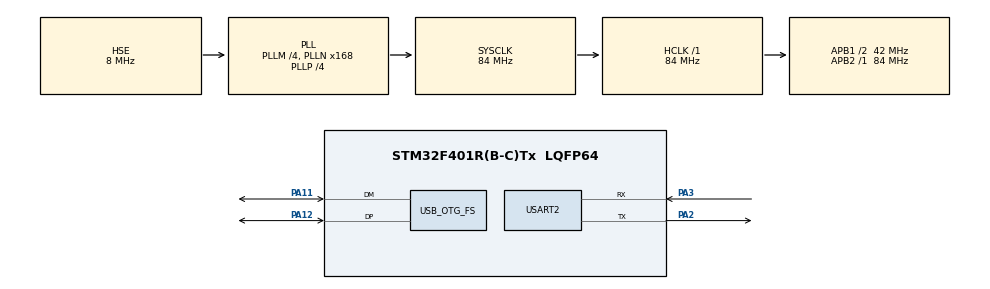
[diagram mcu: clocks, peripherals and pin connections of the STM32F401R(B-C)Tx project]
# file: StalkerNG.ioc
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Mcu.Family=STM32F4
Mcu.Name=STM32F401R(B-C)Tx
Mcu.Package=LQFP64
NVIC.OTG_FS_IRQn=true\:0\:0\:false\:false\:true\:false\:true\:true
NVIC.PriorityGroup=NVIC_PRIORITYGROUP_4
NVIC.TIM1_UP_TIM10_IRQn=true\:15\:0\:false\:false\:true\:false\:true\:true
NVIC.TimeBase=TIM1_UP_TIM10_IRQn
NVIC.TimeBaseIP=TIM1
PA11.Mode=Host_Only
PA11.Signal=USB_OTG_FS_DM
PA12.Mode=Host_Only
PA12.Signal=USB_OTG_FS_DP
PA2.Mode=Asynchronous
PA2.Signal=USART2_TX
PA3.Mode=Asynchronous
PA3.Signal=USART2_RX
PH0\ -\ OSC_IN.Mode=HSE-External-Oscillator
PH0\ -\ OSC_IN.Signal=RCC_OSC_IN
PH1\ -\ OSC_OUT.Mode=HSE-External-Oscillator
PH1\ -\ OSC_OUT.Signal=RCC_OSC_OUT
ProjectManager.HeapSize=0x200
ProjectManager.StackSize=0x400
ProjectManager.TargetToolchain=Makefile
RCC.48MHZClocksFreq_Value=48000000
RCC.AHBFreq_Value=84000000
RCC.APB1CLKDivider=RCC_HCLK_DIV2
RCC.APB1Freq_Value=42000000
RCC.APB1TimFreq_Value=84000000
RCC.APB2Freq_Value=84000000
RCC.APB2TimFreq_Value=84000000
RCC.CortexFreq_Value=84000000
RCC.HCLKFreq_Value=84000000
RCC.HSE_VALUE=8000000
RCC.HSI_VALUE=16000000
RCC.LSE_VALUE=32768
RCC.PLLM=4
RCC.PLLN=168
RCC.PLLP=RCC_PLLP_DIV4
RCC.PLLQ=7
RCC.SYSCLKFreq_VALUE=84000000
RCC.SYSCLKSource=RCC_SYSCLKSOURCE_PLLCLK
RCC.VCOOutputFreq_Value=336000000
USART2.VirtualMode=VM_ASYNC
USB_HOST.USBH_DEBUG_LEVEL=3
USB_HOST.USBH_HandleTypeDef=hUsbHostFS
USB_HOST.USBH_MAX_DATA_BUFFER=1024
USB_HOST.USBH_MAX_NUM_CONFIGURATION=2
USB_HOST.USBH_MAX_NUM_ENDPOINTS=4
USB_HOST.USBH_MAX_NUM_SUPPORTED_CLASS=4
USB_HOST.USBH_MAX_SIZE_CONFIGURATION=512
USB_HOST.VirtualModeFS=Hid
USB_OTG_FS.VirtualMode=Host_Only
USB_OTG_FS.phy_itface=HCD_PHY_EMBEDDED
VP_SYS_VS_tim1.Mode=TIM1
VP_USB_HOST_VS_USB_HOST_HID_FS.Mode=HID_FS
board=custom

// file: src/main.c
/* USER CODE BEGIN Header */
/**
  ******************************************************************************
  * @file           : main.c
  * @brief          : Main program body
  ******************************************************************************
  * @attention
  *
  * Copyright (c) 2025 STMicroelectronics.
  * All rights reserved.
  *
  * This software is licensed under terms that can be found in the LICENSE file
  * in the root directory of this software component.
  * If no LICENSE file comes with this software, it is provided AS-IS.
  *
  ******************************************************************************
  */
/* USER CODE END Header */
#include <stdio.h>
#include "main.h"
#include "usb_host.h"

/* USER CODE BEGIN Includes */
#include "usbh_hid.h"
#include "usbh_hid_keybd.h"
/* USER CODE END Includes */

UART_HandleTypeDef huart2;

/* USER CODE BEGIN PV */
extern ApplicationTypeDef Appli_state;
extern USBH_HandleTypeDef hUsbHostFS;
/* USER CODE END PV */

void SystemClock_Config(void);
static void MX_GPIO_Init(void);
static void MX_USART2_UART_Init(void);
void MX_USB_HOST_Process(void);

/* USER CODE BEGIN 0 */
#ifdef __GNUC__
  /* With GCC, small printf (option LD Linker->Libraries->Small printf
     set to 'Yes') calls __io_putchar() */
  #define PUTCHAR_PROTOTYPE int __io_putchar(int ch)
#else
  #define PUTCHAR_PROTOTYPE int fputc(int ch, FILE *f)
#endif /* __GNUC__ */

/**
  * @brief  Retargets the C library printf function to the USART.
  * @param  None
  * @retval None
  */
PUTCHAR_PROTOTYPE
{
  /* Place your implementation of fputc here */
  /* e.g. write a character to the USART2 and Loop until the end of transmission */
  HAL_UART_Transmit(&huart2, (uint8_t *)&ch, 1, 0xFFFF);

  return ch;
}
/* USER CODE END 0 */
#include "FreeRTOS.h"
#include "task.h"
void vApplicationStackOverflowHook( TaskHandle_t xTask, char *pcTaskName )
{
	( void ) pcTaskName;
	( void ) xTask;
	printf("%s\r\n", __PRETTY_FUNCTION__);
	for (;;);
}

void vApplicationMallocFailedHook( void )
{
	/* The malloc failed hook is enabled by setting
	configUSE_MALLOC_FAILED_HOOK to 1 in FreeRTOSConfig.h.
	Called if a call to pvPortMalloc() fails because there is insufficient
	free memory available in the FreeRTOS heap. pvPortMalloc() is called
	internally by FreeRTOS API functions that create tasks, queues, software
	timers, and semaphores. The size of the FreeRTOS heap is set by the
	configTOTAL_HEAP_SIZE configuration constant in FreeRTOSConfig.h. */
	printf("%s\r\n", __PRETTY_FUNCTION__);
	for( ;; );
}
extern void vApplicationMallocFailedHook( void );

void vApplicationTickHook( void )
{
    /* This function will be called by each tick interrupt if
    configUSE_TICK_HOOK is set to 1 in FreeRTOSConfig.h.
    User code can be added here, but the tick hook is normally
    just used to increment a counter to simulate a software clock. */
}

void LedTask(void *argument)
{
	printf("LedTask Running...\n\r");
	while (1)
	{
		led_on();
		vTaskDelay(pdMS_TO_TICKS(200));
		led_off();
		vTaskDelay(pdMS_TO_TICKS(200));
	}
}

void USBTask(void *argument)
{
	HID_KEYBD_Info_TypeDef *keybd_info;
	static char last_char = 0;
	char c;
	ApplicationTypeDef last_state = APPLICATION_DISCONNECT;

	printf("USBTask Running...\r\n");

	while (1)
	{
		/* USER CODE END WHILE */
		MX_USB_HOST_Process();

		/* USER CODE BEGIN 3 */

		switch (Appli_state)
		{
			case APPLICATION_READY:
			  if (last_state != Appli_state)
				  printf("APPLICATION_READY\r\n");

			  keybd_info = USBH_HID_GetKeybdInfo(&hUsbHostFS);

			  if(keybd_info != NULL)
			  {
				c = USBH_HID_GetASCIICode(keybd_info);
				if (c != 0 && c != last_char)
				{
				  printf("--> KeyCode: %c\n\r", c);
				  fflush(stdout);
				  last_char = c;
				}
				else if (c == 0)
				{
				  last_char = 0; // Reset on key release
				}
			  }
		  break;

		 case APPLICATION_IDLE:
			if (last_state != Appli_state)
				printf("APPLICATION IDLE\r\n");
			break;

		case APPLICATION_START:
			if (last_state != Appli_state)
				printf("APPLICATION START\r\n");
			break;

		case APPLICATION_DISCONNECT:
			if (last_state != Appli_state)
				printf("APPLICATION DISCONNECT\r\n");
		default:
			break;
		}
		last_state = Appli_state;
		/* USER CODE END 3 */
	}

}

int main(void)
{

  /* MCU Configuration--------------------------------------------------------*/

  /* Reset of all peripherals, Initializes the Flash interface and the Systick. */
  HAL_Init();

  /* Configure the system clock */
  SystemClock_Config();

  /* Initialize all configured peripherals */
  MX_GPIO_Init();
  MX_USART2_UART_Init();
  /* Da questo momento la printf e' su debug */
  printf("MAIN CALLED\r\n");
  MX_USB_HOST_Init();
  /* USER CODE BEGIN 2 */
  if ( xTaskCreate( USBTask, "USB Task", configMINIMAL_STACK_SIZE * 4, NULL, tskIDLE_PRIORITY + 2, NULL) != pdPASS )
  {
	printf("Error on creating USB task\n\r");
	while (1) ;;
  }

  if ( xTaskCreate( LedTask, "Led Task", configMINIMAL_STACK_SIZE * 4, NULL, tskIDLE_PRIORITY + 2, NULL) != pdPASS )
  {
	printf("Error on creating LED task\n\r");
	while (1) ;;
  }

  vTaskStartScheduler();

  /* USER CODE END 2 */

  /* Infinite loop */
  /* USER CODE BEGIN WHILE */
  while (1)
  {
  }
}

void SystemClock_Config(void)
{
  RCC_OscInitTypeDef RCC_OscInitStruct = {0};
  RCC_ClkInitTypeDef RCC_ClkInitStruct = {0};

  /** Configure the main internal regulator output voltage
  */
  __HAL_RCC_PWR_CLK_ENABLE();
  __HAL_PWR_VOLTAGESCALING_CONFIG(PWR_REGULATOR_VOLTAGE_SCALE2);

  /** Initializes the RCC Oscillators according to the specified parameters
  * in the RCC_OscInitTypeDef structure.
  */
  RCC_OscInitStruct.OscillatorType = RCC_OSCILLATORTYPE_HSE;
  RCC_OscInitStruct.HSEState = RCC_HSE_ON;
  RCC_OscInitStruct.PLL.PLLState = RCC_PLL_ON;
  RCC_OscInitStruct.PLL.PLLSource = RCC_PLLSOURCE_HSE;
  RCC_OscInitStruct.PLL.PLLM = 4;
  RCC_OscInitStruct.PLL.PLLN = 168;
  RCC_OscInitStruct.PLL.PLLP = RCC_PLLP_DIV4;
  RCC_OscInitStruct.PLL.PLLQ = 7;
  if (HAL_RCC_OscConfig(&RCC_OscInitStruct) != HAL_OK)
  {
    Error_Handler();
  }

  /** Initializes the CPU, AHB and APB buses clocks
  */
  RCC_ClkInitStruct.ClockType = RCC_CLOCKTYPE_HCLK|RCC_CLOCKTYPE_SYSCLK
                              |RCC_CLOCKTYPE_PCLK1|RCC_CLOCKTYPE_PCLK2;
  RCC_ClkInitStruct.SYSCLKSource = RCC_SYSCLKSOURCE_PLLCLK;
  RCC_ClkInitStruct.AHBCLKDivider = RCC_SYSCLK_DIV1;
  RCC_ClkInitStruct.APB1CLKDivider = RCC_HCLK_DIV2;
  RCC_ClkInitStruct.APB2CLKDivider = RCC_HCLK_DIV1;

  if (HAL_RCC_ClockConfig(&RCC_ClkInitStruct, FLASH_LATENCY_2) != HAL_OK)
  {
    Error_Handler();
  }
}

static void MX_USART2_UART_Init(void)
{

  huart2.Instance = USART2;
  huart2.Init.BaudRate = 115200;
  huart2.Init.WordLength = UART_WORDLENGTH_8B;
  huart2.Init.StopBits = UART_STOPBITS_1;
  huart2.Init.Parity = UART_PARITY_NONE;
  huart2.Init.Mode = UART_MODE_TX_RX;
  huart2.Init.HwFlowCtl = UART_HWCONTROL_NONE;
  huart2.Init.OverSampling = UART_OVERSAMPLING_16;
  if (HAL_UART_Init(&huart2) != HAL_OK)
  {
    Error_Handler();
  }

}

static void MX_GPIO_Init(void)
{
  GPIO_InitTypeDef GPIO_InitStruct = {0};

  /* GPIO Ports Clock Enable */
  __HAL_RCC_GPIOC_CLK_ENABLE();
  __HAL_RCC_GPIOH_CLK_ENABLE();
  __HAL_RCC_GPIOA_CLK_ENABLE();
  __HAL_RCC_GPIOB_CLK_ENABLE();
  __HAL_RCC_GPIOD_CLK_ENABLE();

  /*Configure GPIO pin Output Level */
  HAL_GPIO_WritePin(LED_PIN_GPIO_Port, LED_PIN_Pin, GPIO_PIN_RESET);

  /*Configure GPIO pins : PC13 PC14 PC15 PC0
                           PC1 PC2 PC3 PC4
                           PC5 PC6 PC7 PC8
                           PC9 PC10 PC11 PC12 */
  GPIO_InitStruct.Pin = GPIO_PIN_13|GPIO_PIN_14|GPIO_PIN_15|GPIO_PIN_0
                          |GPIO_PIN_1|GPIO_PIN_2|GPIO_PIN_3|GPIO_PIN_4
                          |GPIO_PIN_5|GPIO_PIN_6|GPIO_PIN_7|GPIO_PIN_8
                          |GPIO_PIN_9|GPIO_PIN_10|GPIO_PIN_11|GPIO_PIN_12;
  GPIO_InitStruct.Mode = GPIO_MODE_ANALOG;
  GPIO_InitStruct.Pull = GPIO_NOPULL;
  HAL_GPIO_Init(GPIOC, &GPIO_InitStruct);

  /*Configure GPIO pins : PA1 PA4 PA5
                           PA6 PA7 PA8 PA9
                           PA10 PA13 PA14 PA15 */
  GPIO_InitStruct.Pin = GPIO_PIN_1|GPIO_PIN_4|GPIO_PIN_5
                          |GPIO_PIN_6|GPIO_PIN_7|GPIO_PIN_8|GPIO_PIN_9
                          |GPIO_PIN_10|GPIO_PIN_13|GPIO_PIN_14|GPIO_PIN_15;
  GPIO_InitStruct.Mode = GPIO_MODE_ANALOG;
  GPIO_InitStruct.Pull = GPIO_NOPULL;
  HAL_GPIO_Init(GPIOA, &GPIO_InitStruct);

  /*Configure GPIO pin : LED_PIN_Pin */
  GPIO_InitStruct.Pin = LED_PIN_Pin;
  GPIO_InitStruct.Mode = GPIO_MODE_OUTPUT_PP;
  GPIO_InitStruct.Pull = GPIO_NOPULL;
  GPIO_InitStruct.Speed = GPIO_SPEED_FREQ_LOW;
  HAL_GPIO_Init(LED_PIN_GPIO_Port, &GPIO_InitStruct);

  /*Configure GPIO pins : PB0 PB1 PB2 PB10
                           PB12 PB13 PB14 PB15
                           PB3 PB4 PB5 PB6
                           PB7 PB8 PB9 */
  GPIO_InitStruct.Pin = GPIO_PIN_0|GPIO_PIN_1|GPIO_PIN_2|GPIO_PIN_10
                          |GPIO_PIN_12|GPIO_PIN_13|GPIO_PIN_14|GPIO_PIN_15
                          |GPIO_PIN_3|GPIO_PIN_4|GPIO_PIN_5|GPIO_PIN_6
                          |GPIO_PIN_7|GPIO_PIN_8|GPIO_PIN_9;
  GPIO_InitStruct.Mode = GPIO_MODE_ANALOG;
  GPIO_InitStruct.Pull = GPIO_NOPULL;
  HAL_GPIO_Init(GPIOB, &GPIO_InitStruct);

  /*Configure GPIO pin : PD2 */
  GPIO_InitStruct.Pin = GPIO_PIN_2;
  GPIO_InitStruct.Mode = GPIO_MODE_ANALOG;
  GPIO_InitStruct.Pull = GPIO_NOPULL;
  HAL_GPIO_Init(GPIOD, &GPIO_InitStruct);

}

/* USER CODE BEGIN 4 */
void led_on(void)
{
  HAL_GPIO_WritePin(LED_PIN_GPIO_Port, LED_PIN_Pin, GPIO_PIN_SET);
}

void led_off(void)
{
  HAL_GPIO_WritePin(LED_PIN_GPIO_Port, LED_PIN_Pin, GPIO_PIN_RESET);
}

void led_toggle(void)
{
  HAL_GPIO_TogglePin(LED_PIN_GPIO_Port, LED_PIN_Pin);
}

/* USER CODE END 4 */

void HAL_TIM_PeriodElapsedCallback(TIM_HandleTypeDef *htim)
{
  if (htim->Instance == TIM1)
  {
    HAL_IncTick();
  }
}

void Error_Handler(void)
{
  __disable_irq();
  while (1)
  {
  }
}
